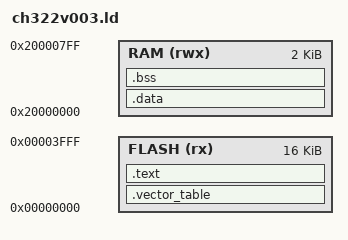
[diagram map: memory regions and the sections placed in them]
ENTRY(_start);

MEMORY
{
    FLASH (rx)  : ORIGIN = 0x00000000, LENGTH = 16K
    RAM   (rwx) : ORIGIN = 0x20000000, LENGTH = 2K
}

SECTIONS
{
    .vector_table : {
        KEEP(*(.vector_table))
    } > FLASH

    .text : {
        *(.text .text.*)
        *(.rodata .rodata.*)
        . = ALIGN(4);
        _etext = .;
    } > FLASH

    .data : AT(_etext) {
        _sdata = .;
        *(.data .data.*)
        . = ALIGN(4);
        _edata = .;
    } > RAM

    .bss (NOLOAD) : {
        _sbss = .;
        *(.bss .bss.*)
        *(COMMON)
        . = ALIGN(4);
        _ebss = .;
    } > RAM

    _stack_top = ORIGIN(RAM) + LENGTH(RAM);
}
